AUTOSAR XML (schema 4-2-1)
package /RootP_ASWC_A7C
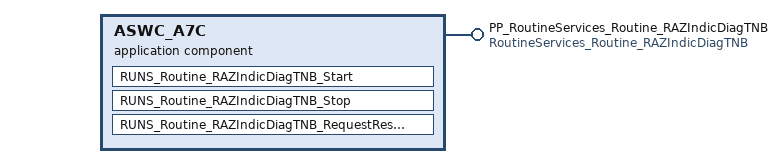
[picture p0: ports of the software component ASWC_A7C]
  application sw component type ASWC_A7C
    provide port PP_RoutineServices_Routine_RAZIndicDiagTNB: provided-interface=RoutineServices_Routine_RAZIndicDiagTNB
      provided-com-specs:
        operation=Start, queue-length=1
        operation=Stop, queue-length=1
        operation=RequestResults, queue-length=1
    behavior IB_ASWC_A7C: data-type-mapping=ApplicationModeMapping, handle-termination-and-restart=NO-SUPPORT
      operation invoked event RoutineServices_Routine_RAZIndicDiagTNB_Start_OIE: start-on-event=RUNS_Routine_RAZIndicDiagTNB_Start, operation=PP_RoutineServices_Routine_RAZIndicDiagTNB.Start
      operation invoked event RoutineServices_Routine_RAZIndicDiagTNB_Stop_OIE: start-on-event=RUNS_Routine_RAZIndicDiagTNB_Stop, operation=PP_RoutineServices_Routine_RAZIndicDiagTNB.Stop
      operation invoked event RoutineServices_Routine_RAZIndicDiagTNB_RequestResults_OIE: start-on-event=RUNS_Routine_RAZIndicDiagTNB_RequestResults, operation=PP_RoutineServices_Routine_RAZIndicDiagTNB.RequestResults
      runnable RUNS_Routine_RAZIndicDiagTNB_Start
      runnable RUNS_Routine_RAZIndicDiagTNB_Stop
      runnable RUNS_Routine_RAZIndicDiagTNB_RequestResults
package /AUTOSAR_Dcm/PortInterfaces
  28 x client server interface, all with is-service=true:
    DataServices_DcmDspData_DID_ACQUI_PRESENCE_PASS
      operation ReadData
        arg Data: type=tBYTE, direction=OUT
      operation WriteData
        arg Data: type=tBYTE, direction=IN
        arg ErrorCode: type=tBYTE, direction=OUT
    DataServices_DcmDspData_DID_BARRETTE_TNB_SUR_LIN
      operation ReadData
        arg Data: type=tBYTE, direction=OUT
      operation WriteData
        arg Data: type=tBYTE, direction=IN
        arg ErrorCode: type=tBYTE, direction=OUT
    DataServices_DcmDspData_DID_CLE_INHIB_AIRBAG
      operation ReadData
        arg Data: type=tBYTE, direction=OUT
      operation WriteData
        arg Data: type=tBYTE, direction=IN
        arg ErrorCode: type=tBYTE, direction=OUT
    DataServices_DcmDspData_DID_DefautPresenceConducteur
      operation ReadData
        arg Data: type=tBYTE, direction=OUT
    DataServices_DcmDspData_DID_DETECTION_PRES_NB_PAR2C
      operation ReadData
        arg Data: type=tBYTE, direction=OUT
      operation WriteData
        arg Data: type=tBYTE, direction=IN
        arg ErrorCode: type=tBYTE, direction=OUT
    DataServices_DcmDspData_DID_DETECTION_PRES_NB_PAR2D
      operation ReadData
        arg Data: type=tBYTE, direction=OUT
      operation WriteData
        arg Data: type=tBYTE, direction=IN
        arg ErrorCode: type=tBYTE, direction=OUT
    DataServices_DcmDspData_DID_DETECTION_PRES_NB_PAR2G
      operation ReadData
        arg Data: type=tBYTE, direction=OUT
      operation WriteData
        arg Data: type=tBYTE, direction=IN
        arg ErrorCode: type=tBYTE, direction=OUT
    DataServices_DcmDspData_DID_FlagDebouclCeintCond
      operation ReadData
        arg Data: type=tBYTE, direction=OUT
    DataServices_DcmDspData_DID_FlagDebouclCeintPassAV
      operation ReadData
        arg Data: type=tBYTE, direction=OUT
    DataServices_DcmDspData_DID_FlagDebouclCeintPavC
      operation ReadData
        arg Data: type=tBYTE, direction=OUT
    DataServices_DcmDspData_DID_FlagDebouclCeintRang2Centre
      operation ReadData
        arg Data: type=tBYTE, direction=OUT
    DataServices_DcmDspData_DID_FlagDebouclCeintRang2Droite
      operation ReadData
        arg Data: type=tBYTE, direction=OUT
    DataServices_DcmDspData_DID_FlagDebouclCeintRang2Gauche
      operation ReadData
        arg Data: type=tBYTE, direction=OUT
    DataServices_DcmDspData_DID_FlagDebouclCeintRang3Droite
      operation ReadData
        arg Data: type=tBYTE, direction=OUT
    DataServices_DcmDspData_DID_FlagDebouclCeintRang3Gauche
      operation ReadData
        arg Data: type=tBYTE, direction=OUT
    DataServices_DcmDspData_DID_INHIB_DIAG_TNB_COND
      operation ReadData
        arg Data: type=tBYTE, direction=OUT
      operation WriteData
        arg Data: type=tBYTE, direction=IN
        arg ErrorCode: type=tBYTE, direction=OUT
    DataServices_DcmDspData_DID_INHIB_DIAG_TNB_PAR3
      operation ReadData
        arg Data: type=tBYTE, direction=OUT
      operation WriteData
        arg Data: type=tBYTE, direction=IN
        arg ErrorCode: type=tBYTE, direction=OUT
    DataServices_DcmDspData_DID_INHIB_DIAG_TNB_PARC
      operation ReadData
        arg Data: type=tBYTE, direction=OUT
      operation WriteData
        arg Data: type=tBYTE, direction=IN
        arg ErrorCode: type=tBYTE, direction=OUT
    DataServices_DcmDspData_DID_INHIB_DIAG_TNB_PARD
      operation ReadData
        arg Data: type=tBYTE, direction=OUT
      operation WriteData
        arg Data: type=tBYTE, direction=IN
        arg ErrorCode: type=tBYTE, direction=OUT
    DataServices_DcmDspData_DID_INHIB_DIAG_TNB_PARG
      operation ReadData
        arg Data: type=tBYTE, direction=OUT
      operation WriteData
        arg Data: type=tBYTE, direction=IN
        arg ErrorCode: type=tBYTE, direction=OUT
    DataServices_DcmDspData_DID_INHIB_DIAG_TNB_PAV
      operation ReadData
        arg Data: type=tBYTE, direction=OUT
      operation WriteData
        arg Data: type=tBYTE, direction=IN
        arg ErrorCode: type=tBYTE, direction=OUT
    DataServices_DcmDspData_DID_NAPPE_DETECTION_PASS
      operation ReadData
        arg Data: type=tBYTE, direction=OUT
      operation WriteData
        arg Data: type=tBYTE, direction=IN
        arg ErrorCode: type=tBYTE, direction=OUT
    DataServices_DcmDspData_DID_NBR_CNB
      operation ReadData
        arg Data: type=tBYTE, direction=OUT
      operation WriteData
        arg Data: type=tBYTE, direction=IN
        arg ErrorCode: type=tBYTE, direction=OUT
    DataServices_DcmDspData_DID_OPTION_PAVC_PRES_DETECTION
      operation ReadData
        arg Data: type=tBYTE, direction=OUT
      operation WriteData
        arg Data: type=tBYTE, direction=IN
        arg ErrorCode: type=tBYTE, direction=OUT
    DataServices_DcmDspData_DID_OPTION_TAXI
      operation ReadData
        arg Data: type=tBYTE, direction=OUT
      operation WriteData
        arg Data: type=tBYTE, direction=IN
        arg ErrorCode: type=tBYTE, direction=OUT
    DataServices_DcmDspData_DID_PresenceConducteur
      operation ReadData
        arg Data: type=tBYTE, direction=OUT
    DataServices_DcmDspData_DID_PRESENCE_ECR
      operation ReadData
        arg Data: type=tBYTE, direction=OUT
      operation WriteData
        arg Data: type=tBYTE, direction=IN
        arg ErrorCode: type=tBYTE, direction=OUT
    RoutineServices_Routine_RAZIndicDiagTNB
      operation Start
        4 x arg, all with type=uint8:
          dataIn0: direction=IN
          dataOut0: direction=OUT
          ErrorCode: direction=OUT
          OpStatus: direction=IN
      operation Stop
        4 x arg, all with type=uint8:
          dataIn0: direction=IN
          dataOut0: direction=OUT
          ErrorCode: direction=OUT
          OpStatus: direction=IN
      operation RequestResults
        arg dataOut0: type=uint8, direction=OUT
        arg ErrorCode: type=uint8, direction=OUT
        arg OpStatus: type=uint8, direction=IN
